# MCASP_0__CFG register map
Vendor: Texas Instruments
Peripheral module from a debugger description file (folder 66AK2G0x_66AK2G1x).
Registers are 32-bit, read-write, reset 0x0 unless marked. A register's access mark holds for its fields unless they carry their own. Offsets are as the file gives them; lines under a group give offsets from that group; [hi:lo] are bit positions; {n}, {i} and the like mark numbered series; 'fields as' and 'values as' point back to an identical list; <NAME> marks a mode.

## MCASP_0__CFG
0x00 MCASP_REV ro reset 0x44300A02
  [31:0] REV — Identifies revision of peripheral.
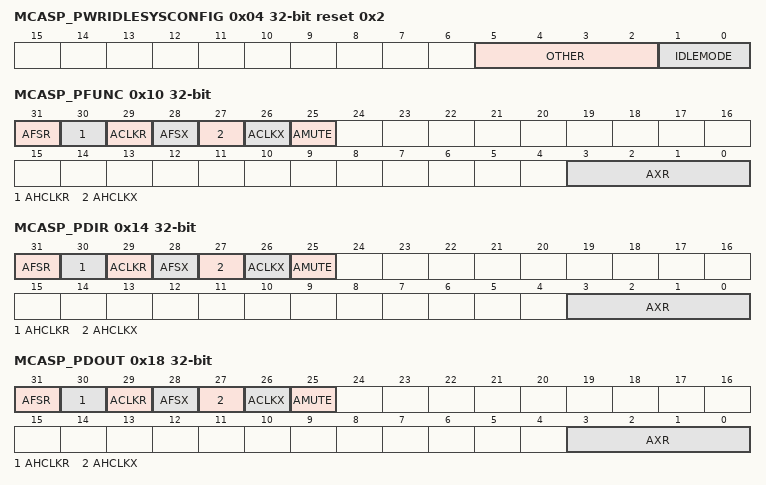
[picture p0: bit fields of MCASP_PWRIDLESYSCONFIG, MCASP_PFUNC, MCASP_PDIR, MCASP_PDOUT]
0x04 MCASP_PWRIDLESYSCONFIG access per field reset 0x2
  [5:2] OTHER rw — Reserved for future programming.
  [1:0] IDLEMODE rw — Power management Configuration of the local target state management mode. By definition, target can handle read/write transaction as long as it is out of IDLE state. 0h (R/W) = Force-idle mode: local target's idle state follows (acknowledges) the system's idle requests unconditionally, i.e. regardless of the IP module's internal requirements. Backup mode, for debug only. 1h (R/W) = No-idle mode: local target never enters idle state. Backup mode, for debug only. 2h (R/W) = Smart-idle mode: local target's idle state eventually follows (acknowledges) the system's idle requests, depending on the IP module's internal requirements. IP module shall not generate (IRQ- or DMA-request-related) wakeup events. 3h (R/W) = Reserved.
0x10 MCASP_PFUNC access per field
  [31] AFSR rw — Determines if AFSR pin functions as McASP or GPIO. 0h (R/W) = Pin functions as McASP pin. 1h (R/W) = Pin functions as GPIO pin.
  [30] AHCLKR rw — Determines if AHCLKR pin functions as McASP or GPIO. 0h (R/W) = Pin functions as McASP pin. 1h (R/W) = Pin functions as GPIO pin.
  [29] ACLKR rw — Determines if ACLKR pin functions as McASP or GPIO. 0h (R/W) = Pin functions as McASP pin. 1h (R/W) = Pin functions as GPIO pin.
  [28] AFSX rw — Determines if AFSX pin functions as McASP or GPIO. 0h (R/W) = Pin functions as McASP pin. 1h (R/W) = Pin functions as GPIO pin.
  [27] AHCLKX rw — Determines if AHCLKX pin functions as McASP or GPIO. 0h (R/W) = Pin functions as McASP pin. 1h (R/W) = Pin functions as GPIO pin.
  [26] ACLKX rw — Determines if ACLKX pin functions as McASP or GPIO. 0h (R/W) = Pin functions as McASP pin. 1h (R/W) = Pin functions as GPIO pin.
  [25] AMUTE rw — Determines if AMUTE pin functions as McASP or GPIO. 0h (R/W) = Pin functions as McASP pin. 1h (R/W) = Pin functions as GPIO pin.
  [3:0] AXR rw — Determines if AXRn pin functions as McASP or GPIO. 0h (R/W) = Pin functions as McASP pin. 1h (R/W) = Pin functions as GPIO pin.
0x14 MCASP_PDIR access per field
  [31] AFSR rw — Determines if AFSR pin functions as an input or output. 0h (R/W) = Pin functions as input. 1h (R/W) = Pin functions as output.
  [30] AHCLKR rw — Determines if AHCLKR pin functions as an input or output. 0h (R/W) = Pin functions as input. 1h (R/W) = Pin functions as output.
  [29] ACLKR rw — Determines if ACLKR pin functions as an input or output. 0h (R/W) = Pin functions as input. 1h (R/W) = Pin functions as output.
  [28] AFSX rw — Determines if AFSX pin functions as an input or output. 0h (R/W) = Pin functions as input. 1h (R/W) = Pin functions as output.
  [27] AHCLKX rw — Determines if AHCLKX pin functions as an input or output. 0h (R/W) = Pin functions as input. 1h (R/W) = Pin functions as output.
  [26] ACLKX rw — Determines if ACLKX pin functions as an input or output. 0h (R/W) = Pin functions as input. 1h (R/W) = Pin functions as output.
  [25] AMUTE rw — Determines if AMUTE pin functions as an input or output. 0h (R/W) = Pin functions as input. 1h (R/W) = Pin functions as output.
  [3:0] AXR rw — Determines if AXRn pin functions as an input or output. 0h (R/W) = Pin functions as input. 1h (R/W) = Pin functions as output.
0x18 MCASP_PDOUT access per field
  [31] AFSR rw — Determines drive on AFSR output pin when the corresponding 0h (R/W) = Pin drives low. 1h (R/W) = Pin drives high.
  [30] AHCLKR rw — Determines drive on AHCLKR output pin when the corresponding 0h (R/W) = Pin drives low. 1h (R/W) = Pin drives high.
  [29] ACLKR rw — Determines drive on ACLKR output pin when the corresponding 0h (R/W) = Pin drives low. 1h (R/W) = Pin drives high.
  [28] AFSX rw — Determines drive on AFSX output pin when the corresponding 0h (R/W) = Pin drives low. 1h (R/W) = Pin drives high.
  [27] AHCLKX rw — Determines drive on AHCLKX output pin when the corresponding 0h (R/W) = Pin drives low. 1h (R/W) = Pin drives high.
  [26] ACLKX rw — Determines drive on ACLKX output pin when the corresponding 0h (R/W) = Pin drives low. 1h (R/W) = Pin drives high.
  [25] AMUTE rw — Determines drive on AMUTE output pin when the corresponding 0h (R/W) = Pin drives low. 1h (R/W) = Pin drives high.
  [3:0] AXR rw — Determines drive on AXR[n] output pin when the corresponding 0h (R/W) = Pin drives low. 1h (R/W) = Pin drives high.
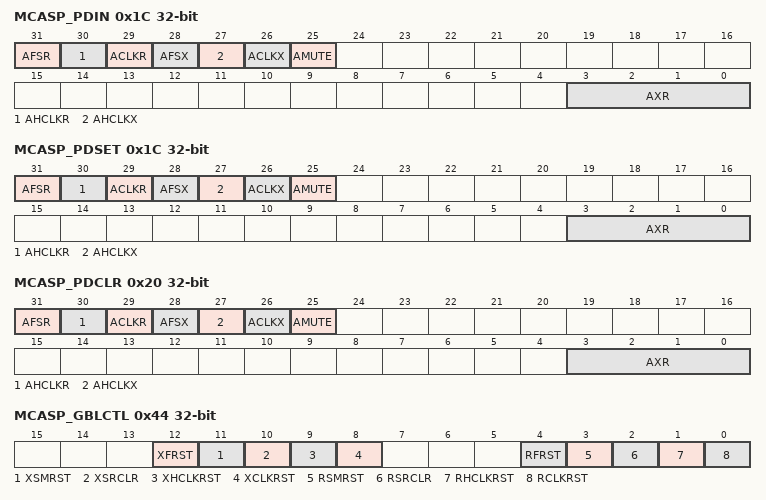
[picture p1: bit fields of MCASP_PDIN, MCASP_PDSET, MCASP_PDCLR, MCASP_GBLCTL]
0x1C MCASP_PDIN access per field
  [31] AFSR rw — Logic level on AFSR pin. 0h (R/W) = Pin is logic low. 1h (R/W) = Pin is logic high.
  [30] AHCLKR rw — Logic level on AHCLKR pin. 0h (R/W) = Pin is logic low. 1h (R/W) = Pin is logic high.
  [29] ACLKR rw — Logic level on ACLKR pin. 0h (R/W) = Pin is logic low. 1h (R/W) = Pin is logic high.
  [28] AFSX rw — Logic level on AFSX pin. 0h (R/W) = Pin is logic low. 1h (R/W) = Pin is logic high.
  [27] AHCLKX rw — Logic level on AHCLKX pin. 0h (R/W) = Pin is logic low. 1h (R/W) = Pin is logic high.
  [26] ACLKX rw — Logic level on ACLKX pin. 0h (R/W) = Pin is logic low. 1h (R/W) = Pin is logic high.
  [25] AMUTE rw — Logic level on AMUTE pin. 0h (R/W) = Pin is logic low. 1h (R/W) = Pin is logic high.
  [3:0] AXR rw — Logic level on AXR[n] pin. 0h (R/W) = Pin is logic low. 1h (R/W) = Pin is logic high.
0x1C MCASP_PDSET access per field
  [31] AFSR wo — Logic level on AFSR pin. 0h (W) = No effect 1h (W) = MACSP_PDOUT[31] bit is set to 1
  [30] AHCLKR wo — Logic level on AHCLKR pin. 0h (W) = No effect 1h (W) = MACSP_PDOUT[30] bit is set to 1
  [29] ACLKR wo — Logic level on ACLKR pin. 0h (W) = No effect 1h (W) = MACSP_PDOUT[29] bit is set to 1
  [28] AFSX wo — Logic level on AFSX pin. 0h (W) = No effect 1h (W) = MACSP_PDOUT[28] bit is set to 1
  [27] AHCLKX rw — Logic level on AHCLKX pin. 0h (W) = No effect 1h (W) = MACSP_PDOUT[27] bit is set to 1
  [26] ACLKX wo — Logic level on ACLKX pin. 0h (W) = No effect 1h (W) = MACSP_PDOUT[26] bit is set to 1
  [25] AMUTE wo — Logic level on AMUTE pin. 0h (W) = No effect 1h (W) = MACSP_PDOUT[25] bit is set to 1
  [3:0] AXR wo — Logic level on AXR[n] pin. 0h (W) = No effect 1h (W) = MACSP_PDOUT[3-0] bits is set to 1
0x20 MCASP_PDCLR access per field
  [31] AFSR rw — Allows the corresponding AFSR bit in 0h (R/W) = No effect. 1h (R/W) =
  [30] AHCLKR rw — Allows the corresponding AHCLKR bit in 0h (R/W) = No effect. 1h (R/W) =
  [29] ACLKR rw — Allows the corresponding ACLKR bit in 0h (R/W) = No effect. 1h (R/W) =
  [28] AFSX rw — Allows the corresponding AFSX bit in 0h (R/W) = No effect. 1h (R/W) =
  [27] AHCLKX rw — Allows the corresponding AHCLKX bit in 0h (R/W) = No effect. 1h (R/W) =
  [26] ACLKX rw — Allows the corresponding ACLKX bit in 0h (R/W) = No effect. 1h (R/W) =
  [25] AMUTE rw — Allows the corresponding AMUTE bit in 0h (R/W) = No effect. 1h (R/W) =
  [3:0] AXR rw — Allows the corresponding AXR[n] bit in 0h (R/W) = No effect. 1h (R/W) =
0x44 MCASP_GBLCTL access per field
  [12] XFRST rw — Transmit frame sync generator reset enable bit. 0h (R/W) = Transmit frame sync generator is reset. 1h (R/W) = Transmit frame sync generator is active. When released from reset, the transmit frame sync generator begins counting serial clocks and generating frame sync as programmed.
  [11] XSMRST rw — Transmit state machine reset enable bit. 0h (R/W) = Transmit state machine is held in reset. AXRn pin state: If 1h (R/W) = Transmit state machine is released from reset. When released from reset, the transmit state machine immediately transfers data from XRBUF[n] to XRSR[n]. The transmit state machine sets the underrun flag (XUNDRN) in
  [10] XSRCLR rw — Transmit serializer clear enable bit. By clearing then setting this bit, the transmit buffer is flushed to an empty state (XDATA = 1). If XSMRST = 1, XSRCLR = 1, XDATA = 1, and 0h (R/W) = Transmit serializers are cleared. 1h (R/W) = Transmit serializers are active. When the transmit serializers are first taken out of reset (XSRCLR changes from 0 to 1), the transmit data ready bit (XDATA) in
  [9] XHCLKRST rw — Transmit high-frequency clock divider reset enable bit. 0h (R/W) = Transmit high-frequency clock divider is held in reset and passes through its input as divide-by-1. 1h (R/W) = Transmit high-frequency clock divider is running.
  [8] XCLKRST rw — Transmit clock divider reset enable bit. 0h (R/W) = Transmit clock divider is held in reset. When the clock divider is in reset, it passes through a divide-by-1 of its input. 1h (R/W) = Transmit clock divider is running.
  [4] RFRST rw — Receive frame sync generator reset enable bit. 0h (R/W) = Receive frame sync generator is reset. 1h (R/W) = Receive frame sync generator is active. When released from reset, the receive frame sync generator begins counting serial clocks and generating frame sync as programmed.
  [3] RSMRST rw — Receive state machine reset enable bit. 0h (R/W) = Receive state machine is held in reset. 1h (R/W) = Receive state machine is released from reset. When released from reset, the receive state machine immediately begins detecting frame sync and is ready to receive. Receive TDM time slot begins at slot 0 after reset is released.
  [2] RSRCLR rw — Receive serializer clear enable bit. By clearing then setting this bit, the receive buffer is flushed. 0h (R/W) = Receive serializers are cleared. 1h (R/W) = Receive serializers are active.
  [1] RHCLKRST rw — Receive high-frequency clock divider reset enable bit. 0h (R/W) = Receive high-frequency clock divider is held in reset and passes through its input as divide-by-1. 1h (R/W) = Receive high-frequency clock divider is running.
  [0] RCLKRST rw — Receive high-frequency clock divider reset enable bit. 0h (R/W) = Receive clock divider is held in reset. When the clock divider is in reset, it passes through a divide-by-1 of its input. 1h (R/W) = Receive clock divider is running.
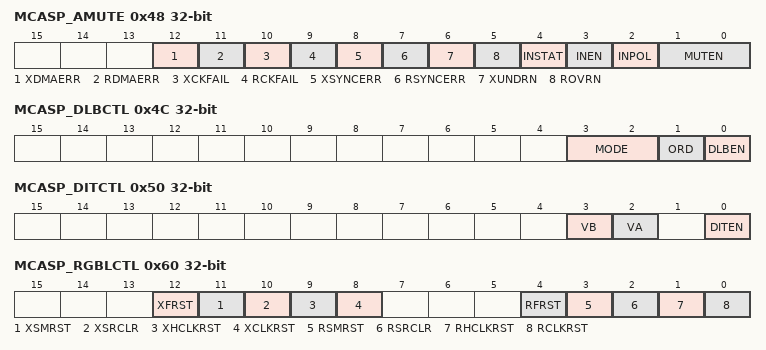
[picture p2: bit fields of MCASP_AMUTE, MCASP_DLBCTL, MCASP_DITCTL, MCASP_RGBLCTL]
0x48 MCASP_AMUTE access per field
  [12] XDMAERR rw — If transmit DMA error (XDMAERR), drive 0h (R/W) = Drive is disabled. Detection of transmit DMA error is ignored by 1h (R/W) = Drive is enabled (active). Upon detection of transmit DMA error,
  [11] RDMAERR rw — If receive DMA error (RDMAERR), drive 0h (R/W) = Drive is disabled. Detection of receive DMA error is ignored by 1h (R/W) = Drive is enabled (active). Upon detection of receive DMA error,
  [10] XCKFAIL rw — If transmit clock failure (XCKFAIL), drive 0h (R/W) = Drive is disabled. Detection of transmit clock failure is ignored by 1h (R/W) = Drive is enabled (active). Upon detection of transmit clock failure,
  [9] RCKFAIL rw — If receive clock failure (RCKFAIL), drive 0h (R/W) = Drive is disabled. Detection of receive clock failure is ignored by 1h (R/W) = Drive is enabled (active). Upon detection of receive clock failure,
  [8] XSYNCERR rw — If unexpected transmit frame sync error (XSYNCERR), drive 0h (R/W) = Drive is disabled. Detection of unexpected transmit frame sync error is ignored by 1h (R/W) = Drive is enabled (active). Upon detection of unexpected transmit frame sync error,
  [7] RSYNCERR rw — If unexpected receive frame sync error (RSYNCERR), drive 0h (R/W) = Drive is disabled. Detection of unexpected receive frame sync error is ignored by 1h (R/W) = Drive is enabled (active). Upon detection of unexpected receive frame sync error,
  [6] XUNDRN rw — If transmit underrun error (XUNDRN), drive 0h (R/W) = Drive is disabled. Detection of transmit underrun error is ignored by 1h (R/W) = Drive is enabled (active). Upon detection of transmit underrun error,
  [5] ROVRN rw — If receiver overrun error (ROVRN), drive 0h (R/W) = Drive is disabled. Detection of receiver overrun error is ignored by 1h (R/W) = Drive is enabled (active). Upon detection of receiver overrun error,
  [4] INSTAT ro — Determines drive on AXRn pin when 0h (R/W) = AMUTEIN pin is inactive. 1h (R/W) = AMUTEIN pin is active. Audio mute in error is detected.
  [3] INEN rw — Drive 0h (R/W) = Drive is disabled. AMUTEIN is ignored by 1h (R/W) = Drive is enabled (active). INSTAT = 1 drives
  [2] INPOL rw — Audio mute in (AMUTEIN) polarity select bit. 0h (R/W) = Polarity is active high. A high on AMUTEIN sets INSTAT to 1. 1h (R/W) = Polarity is active low. A low on AM UTEIN sets INSTAT to 1.
  [1:0] MUTEN rw — 0h (R/W) = 1h (R/W) = 2h (R/W) = 3h (R/W) = Reserved
0x4C MCASP_DLBCTL access per field
  [3:2] MODE rw — Loopback generator mode bits. Applies only when loopback mode is enabled (DLBEN = 1). 0h (R/W) = Default and reserved on loopback mode (DLBEN = 1). When in non-loopback mode (DLBEN = 0), MODE should be left at default (00). When in loopback mode (DLBEN = 1), MODE = 00 is reserved and is not applicable. 1h (R/W) = Transmit clock and frame sync generators used by both transmit and receive sections. When in loopback mode (DLBEN = 1), MODE must be 01. 2h (R/W) = Reserved. 3h (R/W) = Reserved.
  [1] ORD rw — Loopback order bit when loopback mode is enabled (DLBEN = 1). 0h (R/W) = Odd serializers N + 1 transmit to even serializers N that receive. The corresponding serializers must be programmed properly. 1h (R/W) = Even serializers N transmit to odd serializers N + 1 that receive. The corresponding serializers must be programmed properly.
  [0] DLBEN rw — Loopback mode enable bit. 0h (R/W) = Loopback mode is disabled. 1h (R/W) = Loopback mode is enabled.
0x50 MCASP_DITCTL access per field
  [3] VB rw — Valid bit for odd time slots (DIT right subframe). 0h (R/W) = V bit is 0 during odd DIT subframes. 1h (R/W) = V bit is 1 during odd DIT subframes.
  [2] VA rw — Valid bit for even time slots (DIT left subframe). 0h (R/W) = V bit is 0 during even DIT subframes. 1h (R/W) = V bit is 1 during even DIT subframes.
  [0] DITEN rw — DIT mode enable bit. DITEN should only be changed while the XSMRST bit in 0h (R/W) = DIT mode is disabled. Transmitter operates in TDM or burst mode. 1h (R/W) = DIT mode is enabled. Transmitter operates in DIT encoded mode.
0x60 MCASP_RGBLCTL access per field
  [12] XFRST ro — Transmit frame sync generator reset enable bit. A read of this bit returns the XFRST bit value of
  [11] XSMRST ro — Transmit state machine reset enable bit. A read of this bit returns the XSMRST bit value of
  [10] XSRCLR ro — Transmit serializer clear enable bit. A read of this bit returns the XSRCLR bit value of
  [9] XHCLKRST ro — Transmit high-frequency clock divider reset enable bit. A read of this bit returns the XHCLKRST bit value of
  [8] XCLKRST ro — Transmit clock divider reset enable bit. A read of this bit returns the XCLKRST bit value of
  [4] RFRST rw — Receive frame sync generator reset enable bit. A write to this bit affects the RFRST bit of 0h (R/W) = Receive frame sync generator is reset. 1h (R/W) = Receive frame sync generator is active.
  [3] RSMRST rw — Receive state machine reset enable bit. A write to this bit affects the RSMRST bit of 0h (R/W) = Receive state machine is held in reset. 1h (R/W) = Receive state machine is released from reset.
  [2] RSRCLR rw — Receive serializer clear enable bit. A write to this bit affects the RSRCLR bit of 0h (R/W) = Receive serializers are cleared. 1h (R/W) = Receive serializers are active.
  [1] RHCLKRST rw — Receive high-frequency clock divider reset enable bit. A write to this bit affects the RHCLKRST bit of 0h (R/W) = Receive high-frequency clock divider is held in reset and passes through its input as divide-by-1. 1h (R/W) = Receive high-frequency clock divider is running.
  [0] RCLKRST rw — Receive clock divider reset enable bit. A write to this bit affects the RCLKRST bit of 0h (R/W) = Receive clock divider is held in reset. 1h (R/W) = Receive clock divider is running.
0x64 MCASP_RMASK
  [31:0] RMASK — Receive data mask n enable bit. 0h (R/W) = Corresponding bit of receive data (after passing through reverse and rotate units) is masked out and then padded with the selected bit pad value (RPAD and RPBIT bits in 1h (R/W) = Corresponding bit of receive data (after passing through reverse and rotate units) is returned to CPU or DMA.
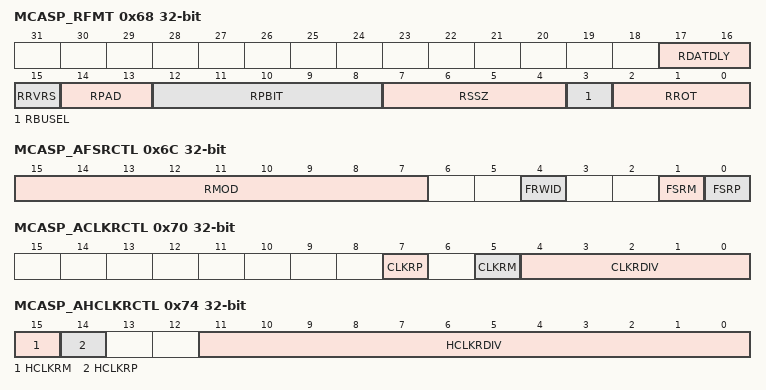
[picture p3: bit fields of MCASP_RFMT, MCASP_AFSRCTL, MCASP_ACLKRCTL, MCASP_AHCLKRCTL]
0x68 MCASP_RFMT access per field
  [17:16] RDATDLY rw — Receive bit delay. 0h (R/W) = 0-bit delay. The first receive data bit, AXRn, occurs in same ACLKR cycle as the receive frame sync (AFSR). 1h (R/W) = 1-bit delay. The first receive data bit, AXRn, occurs one ACLKR cycle after the receive frame sync (AFSR). 2h (R/W) = 2-bit delay. The first receive data bit, AXRn, occurs two ACLKR cycles after the receive frame sync (AFSR). 3h (R/W) = Reserved.
  [15] RRVRS rw — Receive serial bitstream order. 0h (R/W) = Bitstream is LSB first. No bit reversal is performed in receive format bit reverse unit. 1h (R/W) = Bitstream is MSB first. Bit reversal is performed in receive format bit reverse unit.
  [14:13] RPAD rw — Pad value for extra bits in slot not belonging to the word. This field only applies to bits when 0h (R/W) = Pad extra bits with 0. 1h (R/W) = Pad extra bits with 1. 2h (R/W) = Pad extra bits with one of the bits from the word as specified by RPBIT bits. 3h (R/W) = Reserved.
  [12:8] RPBIT rw — RPBIT value determines which bit (as read by the CPU or DMA from 0h (R/W) = Pad with bit 0 value. 1h (R/W) = Pad with bit 1 to bit 31 value from 1h to 1Fh.
  [7:4] RSSZ rw — Receive slot size. 0h (R/W) = Reseved. 1h (R/W) = Reserved. 2h (R/W) = Reserved. 3h (R/W) = Slot size is 8 bits. 4h (R/W) = Reserved 5h (R/W) = Slot size is 12 bits. 6h (R/W) = Reserved 7h (R/W) = Slot size is 16 bits. 8h (R/W) = Reserved 9h (R/W) = Slot size is 20 bits. Ah (R/W) = Reserved Bh (R/W) = Slot size is 24 bits Ch (R/W) = Reserved Dh (R/W) = Slot size is 28 bits. Eh (R/W) = Reserved Fh (R/W) = Slot size is 32 bits.
  [3] RBUSEL rw — Selects whether reads from serializer buffer XRBUF[n] originate from the configuration bus (CFG) or the data (DAT) port. 0h (R/W) = Reads from XRBUF[n] originate on data port. Reads from XRBUF[n] on configuration bus are ignored. 1h (R/W) = Reads from XRBUF[n] originate on configuration bus. Reads from XRBUF[n] on data port are ignored.
  [2:0] RROT rw — Right-rotation value for receive rotate right format unit. 0h (R/W) = Rotate right by 0 (no rotation). 1h (R/W) = Rotate right by 4 bit positions. 2h (R/W) = Rotate right by 8 bit positions. 3h (R/W) = Rotate right by 12 bit positions. 4h (R/W) = Rotate right by 16 bit positions. 5h (R/W) = Rotate right by 20 bit positions. 6h (R/W) = Rotate right by 24 bit positions. 7h (R/W) = Rotate right by 28 bit positions.
0x6C MCASP_AFSRCTL access per field
  [15:7] RMOD rw — Receive frame sync mode select bits. 1FFh = Reserved from 181h to 1FFh. 0h (R/W) = Burst mode. 1h (R/W) = Reserved. 2h (R/W) = 2-slot TDM (I2S mode) to 32-slot TDM from 2h to 20h. 21h (R/W) = Reserved from 21h to 17Fh. 180h (R/W) = 384-slot TDM (external DIR IC inputting 384-slot DIR frames to McASP over I2S interface). 181h (R/W) = Reserved from 181h to 1FFh.
  [4] FRWID rw — Receive frame sync width select bit indicates the width of the receive frame sync (AFSR) during its active period. 0h (R/W) = Single bit. 1h (R/W) = Single word.
  [1] FSRM rw — Receive frame sync generation select bit. 0h (R/W) = Externally-generated receive frame sync. 1h (R/W) = Internally-generated receive frame sync.
  [0] FSRP rw — Receive frame sync polarity select bit. 0h (R/W) = A rising edge on receive frame sync (AFSR) indicates the beginning of a frame. 1h (R/W) = A falling edge on receive frame sync (AFSR) indicates the beginning of a frame.
0x70 MCASP_ACLKRCTL access per field
  [7] CLKRP rw — Receive bitstream clock polarity select bit. 0h (R/W) = Falling edge. Receiver samples data on the falling edge of the serial clock, so the external transmitter driving this receiver must shift data out on the rising edge of the serial clock. 1h (R/W) = Rising edge. Receiver samples data on the rising edge of the serial clock, so the external transmitter driving this receiver must shift data out on the falling edge of the serial clock.
  [5] CLKRM rw — Receive bit clock source bit. Note that this bit does not have any effect, if 0h (R/W) = External receive clock source from ACLKR pin. 1h (R/W) = Internal receive clock source from output of programmable bit clock divider.
  [4:0] CLKRDIV rw — Receive bit clock divide ratio bits determine the divide-down ratio from AHCLKR to ACLKR. Note that this bit does not have any effect, if 0h (R/W) = Divide-by-1. 1h (R/W) = Divide-by-2. 2h (R/W) = Divide-by-3 to divide-by-32 from 2h to 1Fh.
0x74 MCASP_AHCLKRCTL access per field
  [15] HCLKRM rw — Receive high-frequency clock source bit. 0h (R/W) = External receive high-frequency clock source from AHCLKR pin. 1h (R/W) = Internal receive high-frequency clock source from output of programmable high clock divider.
  [14] HCLKRP rw — Receive bitstream high-frequency clock polarity select bit. 0h (R/W) = AHCLKR is not inverted before programmable bit clock divider. In the special case where the receive bit clock (ACLKR) is internally generated and the programmable bit clock divider is set to divide-by-1 (CLKRDIV = 0 in 1h (R/W) = AHCLKR is inverted before programmable bit clock divider. In the special case where the receive bit clock (ACLKR) is internally generated and the programmable bit clock divider is set to divide-by-1 (CLKRDIV = 0 in
  [11:0] HCLKRDIV rw — Receive high-frequency clock divide ratio bits determine the divide-down ratio from AUXCLK to AHCLKR. 0h (R/W) = Divide-by-1. 1h (R/W) = Divide-by-2. 2h (R/W) = Divide-by-3 to divide-by-4096 from 2h to FFFh.
0x78 MCASP_RTDM
  [31:0] RTDMS — Receiver mode during TDM time slot n. 0h (R/W) = Receive TDM time slot n is inactive. The receive serializer does not shift in data during this slot. 1h (R/W) = Receive TDM time slot n is active. The receive serializer shifts in data during this slot.
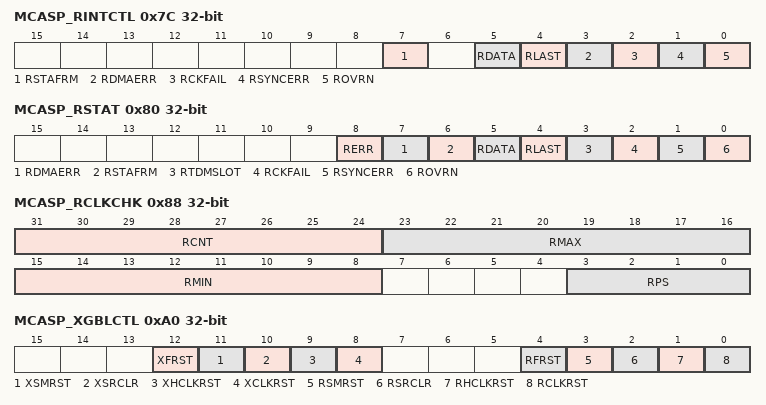
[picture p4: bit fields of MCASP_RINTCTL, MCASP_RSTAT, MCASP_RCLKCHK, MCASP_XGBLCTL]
0x7C MCASP_RINTCTL access per field
  [7] RSTAFRM rw — Receive start of frame interrupt enable bit. 0h (R/W) = Interrupt is disabled. A receive start of frame interrupt does not generate a McASP receive interrupt (RINT). 1h (R/W) = Interrupt is enabled. A receive start of frame interrupt generates a McASP receive interrupt (RINT).
  [5] RDATA rw — Receive data ready interrupt enable bit. 0h (R/W) = Interrupt is disabled. A receive data ready interrupt does not generate a McASP receive interrupt (RINT). 1h (R/W) = Interrupt is enabled. A receive data ready interrupt generates a McASP receive interrupt (RINT).
  [4] RLAST rw — Receive last slot interrupt enable bit. 0h (R/W) = Interrupt is disabled. A receive last slot interrupt does not generate a McASP receive interrupt (RINT). 1h (R/W) = Interrupt is enabled. A receive last slot interrupt generates a McASP receive interrupt (RINT).
  [3] RDMAERR rw — Receive DMA error interrupt enable bit. 0h (R/W) = Interrupt is disabled. A receive DMA error interrupt does not generate a McASP receive interrupt (RINT). 1h (R/W) = Interrupt is enabled. A receive DMA error interrupt generates a McASP receive interrupt (RINT).
  [2] RCKFAIL rw — Receive clock failure interrupt enable bit. 0h (R/W) = Interrupt is disabled. A receive clock failure interrupt does not generate a McASP receive interrupt (RINT). 1h (R/W) = Interrupt is enabled. A receive clock failure interrupt generates a McASP receive interrupt (RINT).
  [1] RSYNCERR rw — Unexpected receive frame sync interrupt enable bit. 0h (R/W) = Interrupt is disabled. An unexpected receive frame sync interrupt does not generate a McASP receive interrupt (RINT). 1h (R/W) = Interrupt is enabled. An unexpected receive frame sync interrupt generates a McASP receive interrupt (RINT).
  [0] ROVRN rw — Receiver overrun interrupt enable bit. 0h (R/W) = Interrupt is disabled. A receiver overrun interrupt does not generate a McASP receive interrupt (RINT). 1h (R/W) = Interrupt is enabled. A receiver overrun interrupt generates a McASP receive interrupt (RINT).
0x80 MCASP_RSTAT access not given
  [8] RERR rw — RERR bit always returns a logic-OR of: ROVRN OR RSYNCERR OR RCKFAIL OR RDMAERR. Allows a single bit to be checked to determine if a receiver error interrupt has occurred. 0h (R/W) = No errors have occurred. 1h (R/W) = An error has occurred.
  [7] RDMAERR — Receive DMA error flag. RDMAERR is set when the CPU or DMA reads more serializers through the data port in a given time slot than were programmed as receivers. Causes a receive interrupt (RINT), if this bit is set and RDMAERR in 0h (R/W) = Receive DMA error did not occur. 1h (R/W) = Receive DMA error did occur. (access RW1C)
  [6] RSTAFRM — Receive start of frame flag. Causes a receive interrupt (RINT), if this bit is set and RSTAFRM in 0h (R/W) = No new receive frame sync (AFSR) is detected. 1h (R/W) = A new receive frame sync (AFSR) is detected. (access RW1C)
  [5] RDATA — Receive data ready flag. Causes a receive interrupt (RINT), if this bit is set and RDATA in 0h (R/W) = No new data in 1h (R/W) = Data is transferred from XRSR to (access RW1C)
  [4] RLAST — Receive last slot flag. RLAST is set along with RDATA, if the current slot is the last slot in a frame. Causes a receive interrupt (RINT), if this bit is set and RLAST in 0h (R/W) = Current slot is not the last slot in a frame. 1h (R/W) = Current slot is the last slot in a frame. RDATA is also set. (access RW1C)
  [3] RTDMSLOT ro — Returns the LSB of 0h (R/W) = Current TDM time slot is odd. 1h (R/W) = Current TDM time slot is even.
  [2] RCKFAIL — Receive clock failure flag. RCKFAIL is set when the receive clock failure detection circuit reports an error. Causes a receive interrupt (RINT), if this bit is set and RCKFAIL in 0h (R/W) = Receive clock failure did not occur. 1h (R/W) = Receive clock failure did occur. (access RW1C)
  [1] RSYNCERR — Unexpected receive frame sync flag. RSYNCERR is set when a new receive frame sync (AFSR) occurs before it is expected. Causes a receive interrupt (RINT), if this bit is set and RSYNCERR in 0h (R/W) = Unexpected receive frame sync did not occur. 1h (R/W) = Unexpected receive frame sync did occur. (access RW1C)
  [0] ROVRN — Receiver overrun flag. ROVRN is set when the receive serializer is instructed to transfer data from XRSR to 0h (R/W) = Receiver overrun did not occur. 1h (R/W) = Receiver overrun did occur. (access RW1C)
0x84 MCASP_RSLOT ro
  [8:0] RSLOTCNT — 0-17Fh = Current receive time slot count. Legal values: 0 to 383 (17Fh). TDM function is not supported for &gt; 32 time slots. However, TDM time slot counter may count to 383 when used to receive a DIR block (transferred over TDM format).
0x88 MCASP_RCLKCHK access per field
  [31:24] RCNT ro — Receive clock count value (from previous measurement). The clock circuit continually counts the number of system clocks for every 32 receive high-frequency master clock (AHCLKR) signals, and stores the count in RCNT until the next measurement is taken.
  [23:16] RMAX rw — Receive clock maximum boundary. This 8 bit unsigned value sets the maximum allowed boundary for the clock check counter after 32 receive high-frequency master clock (AHCLKR) signals have been received. If the current counter value is greater than RMAX after counting 32 AHCLKR signals, RCKFAIL in
  [15:8] RMIN rw — Receive clock minimum boundary. This 8 bit unsigned value sets the minimum allowed boundary for the clock check counter after 32 receive high-frequency master clock (AHCLKR) signals have been received. If RCNT is less than RMIN after counting 32 AHCLKR signals, RCKFAIL in
  [3:0] RPS rw — Receive clock check prescaler value. 0h (R/W) = McASP system clock divided by 1. 1h (R/W) = McASP system clock divided by 2. 2h (R/W) = McASP system clock divided by 4. 3h (R/W) = McASP system clock divided by 8. 4h (R/W) = McASP system clock divided by 16. 5h (R/W) = McASP system clock divided by 32. 6h (R/W) = McASP system clock divided by 64. 7h (R/W) = McASP system clock divided by 128. 8h (R/W) = McASP system clock divided by 256. 9h (R/W) = Reserved from 9h to Fh.
0x8C MCASP_REVTCTL access per field
  [0] RDATDMA rw — Receive data DMA request enable bit. If writing to this bit, always write the default value of 0. 0h (R/W) = Receive data DMA request is enabled. 1h (R/W) = Reserved
0xA0 MCASP_XGBLCTL access per field
  [12] XFRST rw — Transmit frame sync generator reset enable bit. A write to this bit affects the XFRST bit of 0h (R/W) = Transmit frame sync generator is reset. 1h (R/W) = Transmit frame sync generator is active.
  [11] XSMRST rw — Transmit state machine reset enable bit. A write to this bit affects the XSMRST bit of 0h (R/W) = Transmit state machine is held in reset. 1h (R/W) = Transmit state machine is released from reset.
  [10] XSRCLR rw — Transmit serializer clear enable bit. A write to this bit affects the XSRCLR bit of 0h (R/W) = Transmit serializers are cleared. 1h (R/W) = Transmit serializers are active.
  [9] XHCLKRST rw — Transmit high-frequency clock divider reset enable bit. A write to this bit affects the XHCLKRST bit of 0h (R/W) = Transmit high-frequency clock divider is held in reset. 1h (R/W) = Transmit high-frequency clock divider is running.
  [8] XCLKRST rw — Transmit clock divider reset enable bit. A write to this bit affects the XCLKRST bit of 0h (R/W) = Transmit clock divider is held in reset. 1h (R/W) = Transmit clock divider is running.
  [4] RFRST ro — Receive frame sync generator reset enable bit. A read of this bit returns the RFRST bit value of
  [3] RSMRST ro — Receive state machine reset enable bit. A read of this bit returns the RSMRST bit value of
  [2] RSRCLR ro — Receive serializer clear enable bit. A read of this bit returns the RSRSCLR bit value of
  [1] RHCLKRST ro — Receive high-frequency clock divider reset enable bit. A read of this bit returns the RHCLKRST bit value of
  [0] RCLKRST ro — Receive clock divider reset enable bit. A read of this bit returns the RCLKRST bit value of
0xA4 MCASP_XMASK
  [31:0] XMASK — Transmit data mask n enable bit. 0h (R/W) = Corresponding bit of transmit data (before passing through reverse and rotate units) is masked out and then padded with the selected bit pad value (XPAD and XPBIT bits in 1h (R/W) = Corresponding bit of transmit data (before passing through reverse and rotate units) is transmitted out the McASP.
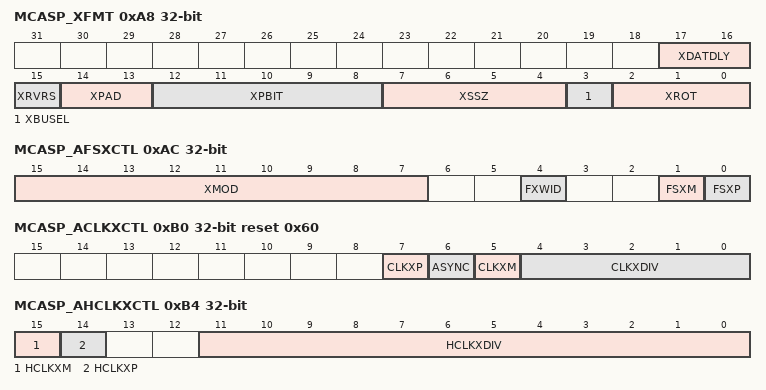
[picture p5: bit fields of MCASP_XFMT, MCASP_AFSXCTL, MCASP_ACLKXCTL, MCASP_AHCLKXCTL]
0xA8 MCASP_XFMT access per field
  [17:16] XDATDLY rw — Transmit sync bit delay. 0h (R/W) = 0-bit delay. The first transmit data bit, AXRn, occurs in same ACLKX cycle as the transmit frame sync (AFSX). 1h (R/W) = 1-bit delay. The first transmit data bit, AXRn, occurs one ACLKX cycle after the transmit frame sync (AFSX). 2h (R/W) = 2-bit delay. The first transmit data bit, AXRn, occurs two ACLKX cycles after the transmit frame sync (AFSX). 3h (R/W) = Reserved.
  [15] XRVRS rw — Transmit serial bitstream order. 0h (R/W) = Bitstream is LSB first. No bit reversal is performed in transmit format bit reverse unit. 1h (R/W) = Bitstream is MSB first. Bit reversal is performed in transmit format bit reverse unit.
  [14:13] XPAD rw — Pad value for extra bits in slot not belonging to word defined by 0h (R/W) = Pad extra bits with 0. 1h (R/W) = Pad extra bits with 1. 2h (R/W) = Pad extra bits with one of the bits from the word as specified by XPBIT bits. 3h (R/W) = Reserved.
  [12:8] XPBIT rw — XPBIT value determines which bit (as written by the CPU or DMA to 0h (R/W) = Pad with bit 0 value. 1h (R/W) = Pad with bit 1 to bit 31 value from 1h to 1Fh.
  [7:4] XSSZ rw — Transmit slot size. 0h (R/W) = Reserved. 1h (R/W) = Reserved. 2h (R/W) = Reserved. 3h (R/W) = Slot size is 8 bits. 4h (R/W) = Reserved. 5h (R/W) = Slot size is 12 bits. 6h (R/W) = Reserved. 7h (R/W) = Slot size is 16 bits. 8h (R/W) = Reserved. 9h (R/W) = Slot size is 20 bits. Ah (R/W) = Reserved. Bh (R/W) = Slot size is 24 bits. Ch (R/W) = Reserved. Dh (R/W) = Slot size is 28 bits. Eh (R/W) = Reserved. Fh (R/W) = Slot size is 32 bits.
  [3] XBUSEL rw — Selects whether writes to serializer buffer XRBUF[n] originate from the configuration bus (CFG) or the data (DAT) port. 0h (R/W) = Writes to XRBUF[n] originate from the data port. Writes to XRBUF[n] from the configuration bus are ignored with no effect to the McASP. 1h (R/W) = Writes to XRBUF[n] originate from the configuration bus. Writes to XRBUF[n] from the data port are ignored with no effect to the McASP.
  [2:0] XROT rw — Right-rotation value for transmit rotate right format unit. 0h (R/W) = Rotate right by 0 (no rotation). 1h (R/W) = Rotate right by 4 bit positions. 2h (R/W) = Rotate right by 8 bit positions. 3h (R/W) = Rotate right by 12 bit positions. 4h (R/W) = Rotate right by 16 bit positions. 5h (R/W) = Rotate right by 20 bit positions. 6h (R/W) = Rotate right by 24 bit positions. 7h (R/W) = Rotate right by 28 bit positions.
0xAC MCASP_AFSXCTL access per field
  [15:7] XMOD rw — Transmit frame sync mode select bits. 1FFh = Reserved from 181h to 1FFh. 0h (R/W) = Burst mode. 1h (R/W) = Reserved. 2h (R/W) = 2-slot TDM (I2S mode) to 32-slot TDM from 2h to 20h. 21h (R/W) = Reserved from 21h to 17Fh. 180h (R/W) = 384-slot DIT mode. 181h (R/W) = Reserved from 181h to 1FFh.
  [4] FXWID rw — Transmit frame sync width select bit indicates the width of the transmit frame sync (AFSX) during its active period. 0h (R/W) = Single bit. 1h (R/W) = Single word.
  [1] FSXM rw — Transmit frame sync generation select bit. 0h (R/W) = Externally-generated transmit frame sync. 1h (R/W) = Internally-generated transmit frame sync.
  [0] FSXP rw — Transmit frame sync polarity select bit. 0h (R/W) = A rising edge on transmit frame sync (AFSX) indicates the beginning of a frame. 1h (R/W) = A falling edge on transmit frame sync (AFSX) indicates the beginning of a frame.
0xB0 MCASP_ACLKXCTL access per field reset 0x60
  [7] CLKXP rw — Transmit bitstream clock polarity select bit. 0h (R/W) = Rising edge. External receiver samples data on the falling edge of the serial clock, so the transmitter must shift data out on the rising edge of the serial clock. 1h (R/W) = Falling edge. External receiver samples data on the rising edge of the serial clock, so the transmitter must shift data out on the falling edge of the serial clock.
  [6] ASYNC rw — Transmit/receive operation asynchronous enable bit. 0h (R/W) = Synchronous. Transmit clock and frame sync provides the source for both the transmit and receive sections. 1h (R/W) = Asynchronous. Separate clock and frame sync used by transmit and receive sections.
  [5] CLKXM rw — Transmit bit clock source bit. 0h (R/W) = External transmit clock source from ACLKX pin. 1h (R/W) = Internal transmit clock source from output of programmable bit clock divider.
  [4:0] CLKXDIV rw — Transmit bit clock divide ratio bits determine the divide-down ratio from AHCLKX to ACLKX. 0h (R/W) = Divide-by-1. 1h (R/W) = Divide-by-2. 2h (R/W) = Divide-by-3 to divide-by-32 from 2h to 1Fh.
0xB4 MCASP_AHCLKXCTL access per field
  [15] HCLKXM rw — Transmit high-frequency clock source bit. 0h (R/W) = External transmit high-frequency clock source from AHCLKX pin. 1h (R/W) = Internal transmit high-frequency clock source from output of programmable high clock divider.
  [14] HCLKXP rw — Transmit bitstream high-frequency clock polarity select bit. 0h (R/W) = AHCLKX is not inverted before programmable bit clock divider. In the special case where the transmit bit clock (ACLKX) is internally generated and the programmable bit clock divider is set to divide-by-1 (CLKXDIV = 0 in 1h (R/W) = AHCLKX is inverted before programmable bit clock divider. In the special case where the transmit bit clock (ACLKX) is internally generated and the programmable bit clock divider is set to divide-by-1 (CLKXDIV = 0 in
  [11:0] HCLKXDIV rw — Transmit high-frequency clock divide ratio bits determine the divide-down ratio from AUXCLK to AHCLKX. 0h (R/W) = Divide-by-1. 1h (R/W) = Divide-by-2. 2h (R/W) = Divide-by-3 to divide-by-4096 from 2h to FFFh.
0xB8 MCASP_XTDM
  [31:0] XTDMS — Transmitter mode during TDM time slot n. 0h (R/W) = Transmit TDM time slot n is inactive. The transmit serializer does not shift out data during this slot. 1h (R/W) = Transmit TDM time slot n is active. The transmit serializer shifts out data during this slot according to the serializer control register (SRCTL).
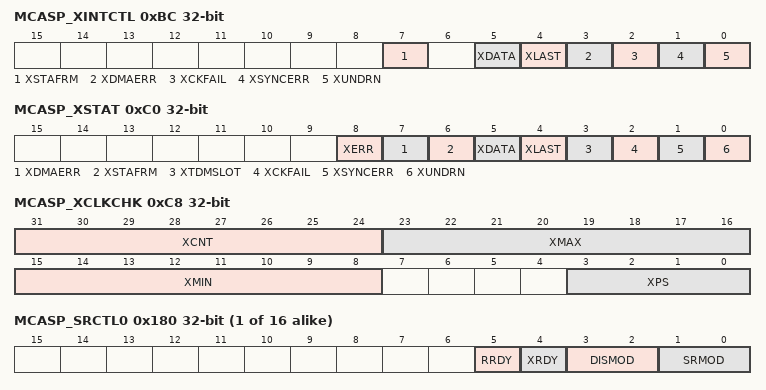
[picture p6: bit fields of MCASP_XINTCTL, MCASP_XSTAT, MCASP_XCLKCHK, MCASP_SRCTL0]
0xBC MCASP_XINTCTL access per field
  [7] XSTAFRM rw — Transmit start of frame interrupt enable bit. 0h (R/W) = Interrupt is disabled. A transmit start of frame interrupt does not generate a McASP transmit interrupt (XINT). 1h (R/W) = Interrupt is enabled. A transmit start of frame interrupt generates a McASP transmit interrupt (XINT).
  [5] XDATA rw — Transmit data ready interrupt enable bit. 0h (R/W) = Interrupt is disabled. A transmit data ready interrupt does not generate a McASP transmit interrupt (XINT). 1h (R/W) = Interrupt is enabled. A transmit data ready interrupt generates a McASP transmit interrupt (XINT).
  [4] XLAST rw — Transmit last slot interrupt enable bit. 0h (R/W) = Interrupt is disabled. A transmit last slot interrupt does not generate a McASP transmit interrupt (XINT). 1h (R/W) = Interrupt is enabled. A transmit last slot interrupt generates a McASP transmit interrupt (XINT).
  [3] XDMAERR rw — Transmit DMA error interrupt enable bit. 0h (R/W) = Interrupt is disabled. A transmit DMA error interrupt does not generate a McASP transmit interrupt (XINT). 1h (R/W) = Interrupt is enabled. A transmit DMA error interrupt generates a McASP transmit interrupt (XINT).
  [2] XCKFAIL rw — Transmit clock failure interrupt enable bit. 0h (R/W) = Interrupt is disabled. A transmit clock failure interrupt does not generate a McASP transmit interrupt (XINT). 1h (R/W) = Interrupt is enabled. A transmit clock failure interrupt generates a McASP transmit interrupt (XINT).
  [1] XSYNCERR rw — Unexpected transmit frame sync interrupt enable bit. 0h (R/W) = Interrupt is disabled. An unexpected transmit frame sync interrupt does not generate a McASP transmit interrupt (XINT). 1h (R/W) = Interrupt is enabled. An unexpected transmit frame sync interrupt generates a McASP transmit interrupt (XINT).
  [0] XUNDRN rw — Transmitter underrun interrupt enable bit. 0h (R/W) = Interrupt is disabled. A transmitter underrun interrupt does not generate a McASP transmit interrupt (XINT). 1h (R/W) = Interrupt is enabled. A transmitter underrun interrupt generates a McASP transmit interrupt (XINT).
0xC0 MCASP_XSTAT access not given
  [8] XERR rw — XERR bit always returns a logic-OR of: XUNDRN OR XSYNCERR OR XCKFAIL OR XDMAERR. Allows a single bit to be checked to determine if a transmitter error interrupt has occurred. 0h (R/W) = No errors have occurred. 1h (R/W) = An error has occurred.
  [7] XDMAERR — Transmit DMA error flag. XDMAERR is set when the CPU or DMA writes more serializers through the data port in a given time slot than were programmed as transmitters. Causes a transmit interrupt (XINT), if this bit is set and XDMAERR in 0h (R/W) = Transmit DMA error did not occur. 1h (R/W) = Transmit DMA error did occur. (access RW1C)
  [6] XSTAFRM — Transmit start of frame flag. Causes a transmit interrupt (XINT), if this bit is set and XSTAFRM in 0h (R/W) = No new transmit frame sync (AFSX) is detected. 1h (R/W) = A new transmit frame sync (AFSX) is detected. (access RW1C)
  [5] XDATA — Transmit data ready flag. Causes a transmit interrupt (XINT), if this bit is set and XDATA in 0h (R/W) = 1h (R/W) = Data is copied from (access RW1C)
  [4] XLAST — Transmit last slot flag. XLAST is set along with XDATA, if the current slot is the last slot in a frame. Causes a transmit interrupt (XINT), if this bit is set and XLAST in 0h (R/W) = Current slot is not the last slot in a frame. 1h (R/W) = Current slot is the last slot in a frame. XDATA is also set. (access RW1C)
  [3] XTDMSLOT ro — Returns the LSB of 0h (R/W) = Current TDM time slot is odd. 1h (R/W) = Current TDM time slot is even.
  [2] XCKFAIL — Transmit clock failure flag. XCKFAIL is set when the transmit clock failure detection circuit reports an error. Causes a transmit interrupt (XINT), if this bit is set and XCKFAIL in 0h (R/W) = Transmit clock failure did not occur. 1h (R/W) = Transmit clock failure did occur. (access RW1C)
  [1] XSYNCERR — Unexpected transmit frame sync flag. XSYNCERR is set when a new transmit frame sync (AFSX) occurs before it is expected. Causes a transmit interrupt (XINT), if this bit is set and XSYNCERR in 0h (R/W) = Unexpected transmit frame sync did not occur. 1h (R/W) = Unexpected transmit frame sync did occur. (access RW1C)
  [0] XUNDRN — Transmitter underrun flag. XUNDRN is set when the transmit serializer is instructed to transfer data from 0h (R/W) = Transmitter underrun did not occur. 1h (R/W) = Transmitter underrun did occur. For details on McASP action upon underrun conditions, see Buffer Underrun Error - Transmitter. (access RW1C)
0xC4 MCASP_XSLOT ro
  [9:0] XSLOTCNT — Current transmit time slot count. Legal values: 0 to 383 (17Fh). During reset, this counter value is 383 so the next count value, which is used to encode the first DIT group of data, will be 0 and encodes the B preamble. TDM function is not supported for &gt;32 time slots. However, TDM time slot counter may count to 383 when used to transmit a DIT block.
0xC8 MCASP_XCLKCHK access per field
  [31:24] XCNT ro — Transmit clock count value (from previous measurement). The clock circuit continually counts the number of system clocks for every 32 transmit high-frequency master clock (AHCLKX) signals, and stores the count in XCNT until the next measurement is taken.
  [23:16] XMAX rw — Transmit clock maximum boundary. This 8 bit unsigned value sets the maximum allowed boundary for the clock check counter after 32 transmit high-frequency master clock (AHCLKX) signals have been received. If the current counter value is greater than XMAX after counting 32 AHCLKX signals, XCKFAIL in
  [15:8] XMIN rw — Transmit clock minimum boundary. This 8 bit unsigned value sets the minimum allowed boundary for the clock check counter after 32 transmit high-frequency master clock (AHCLKX) signals have been received. If XCNT is less than XMIN after counting 32 AHCLKX signals, XCKFAIL in
  [3:0] XPS rw — Transmit clock check prescaler value. Fh = Reserved from 9h to Fh. 0h (R/W) = McASP system clock divided by 1. 1h (R/W) = McASP system clock divided by 2. 2h (R/W) = McASP system clock divided by 4. 3h (R/W) = McASP system clock divided by 8. 4h (R/W) = McASP system clock divided by 16. 5h (R/W) = McASP system clock divided by 32. 6h (R/W) = McASP system clock divided by 64. 7h (R/W) = McASP system clock divided by 128. 8h (R/W) = McASP system clock divided by 256. 9h (R/W) = Reserved from 9h to Fh.
0xCC MCASP_XEVTCTL access per field
  [0] XDATDMA rw — Transmit data DMA request enable bit. If writing to this bit, always write the default value of 0. 0h (R/W) = Transmit data DMA request is enabled. 1h (R/W) = Reserved
{0x100+4i} MCASP_DITCSRA{i} (i=0..5)
  [31:0] DITCSRA — DIT left channel status registers.
{0x118+4i} MCASP_DITCSRB{i} (i=0..5)
  [31:0] DITCSRB — DIT right channel status registers.
{0x130+4i} MCASP_DITUDRA{i} (i=0..5)
  [31:0] DITUDRA — DIT left channel user data registers.
{0x148+4i} MCASP_DITUDRB{i} (i=0..5)
  [31:0] DITUDRB — DIT right channel user data registers.
{0x180+4i} MCASP_SRCTL{i} access per field (i=0..15)
  [5] RRDY ro — Receive buffer ready bit. RRDY indicates the current receive buffer state. Always reads 0 when programmed as a transmitter or as inactive. If SRMOD bit is set to receive (2h), RRDY switches from 0 to 1 whenever data is transferred from XRSR to 0h (R/W) = Receive buffer ( 1h (R/W) = Receive buffer (
  [4] XRDY ro — Transmit buffer ready bit. XRDY indicates the current transmit buffer state. Always reads 0 when programmed as a receiver or as inactive. If SRMOD bit is set to transmit (1h), XRDY switches from 0 to 1 when XSRCLR in 0h (R/W) = Transmit buffer ( 1h (R/W) = Transmit buffer (
  [3:2] DISMOD rw — Serializer pin drive mode bit. Drive on pin when in inactive TDM slot of transmit mode or when serializer is inactive. This field only applies if the pin is configured as a McASP pin ( 0h (R/W) = Drive on pin is 3-state. 1h (R/W) = Reserved. 2h (R/W) = Drive on pin is logic low. 3h (R/W) = Drive on pin is logic high.
  [1:0] SRMOD rw — Serializer mode bit. 0h (R/W) = Serializer is inactive. 1h (R/W) = Serializer is transmitter. 2h (R/W) = Serializer is receiver. 3h (R/W) = Reserved.
{0x200+4i} MCASP_XBUF{i} (i=0..15)
  [31:0] XBUF — Transmit buffers for serializers.
{0x280+4i} MCASP_RBUF{i} (i=0..15)
  [31:0] RBUF — Receive buffers for serializers.
